AUTOSAR XML (schema 4-0-3)
standard types defined: boolean, float32, float64, sint16, sint32, sint8, uint16, uint32, uint8
package /HelloAutosar
  composition sw component type HA_TopLevel
    component SWC1: type=SWC1
    component SWC2: type=SWC2
    connect SWC1.PPort -> SWC2.RPort
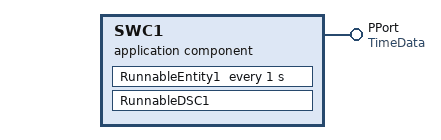
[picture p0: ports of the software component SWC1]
  application sw component type SWC1
    provide port PPort: nonqueued-sender-com-spec{data-element=time, transmission-acknowledge=timeout=1, init-value=Value:0}, provided-interface=TimeData
    behavior IB_SWC1: handle-termination-and-restart=NO-SUPPORT
      timing event TimingEvent: start-on-event=RunnableEntity1, period=1
      data send completed event DataSendCompletedEvent1: start-on-event=RunnableDSC1, event-source=RunnableEntity1/VariableAccess
      runnable RunnableEntity1: can-be-invoked-concurrently=true
        data-send-points:
          access VariableAccess: accessed-variable=PPort.time
      runnable RunnableDSC1: symbol=SWC1_RunnableDSC1
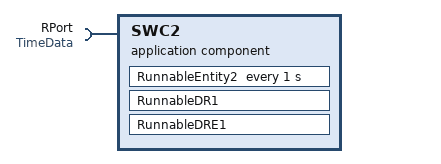
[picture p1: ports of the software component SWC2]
  application sw component type SWC2
    require port RPort: required-interface=TimeData
    behavior IB_SWC2: handle-termination-and-restart=NO-SUPPORT
      timing event TimingEvent: start-on-event=RunnableEntity2, period=1
      data received event DataReceivedEvent1: start-on-event=RunnableDR1, data=RPort.time
      data receive error event DataReceiveErrorEvent1: start-on-event=RunnableDRE1, data=RPort.time
      runnable RunnableEntity2
        data-receive-point-by-arguments:
          access VariableAccess: accessed-variable=RPort.time
      runnable RunnableDR1: can-be-invoked-concurrently=true, symbol=SWC2_RunnableDR1
        data-receive-point-by-arguments:
          access DataReceivePointByArgument: accessed-variable=RPort.time
      runnable RunnableDRE1: can-be-invoked-concurrently=true, symbol=SWC2_RunnableDRE1
        data-receive-point-by-arguments:
          access DataReceivePointByArgument: accessed-variable=RPort.time
package /ImplDataTypes
  impl type IDT_TimeCount: category=VALUE, base-type=uint32, invalid-value=10
package /Interfaces
  sender receiver interface TimeData: invalidation-policy{data-element=time, handle-invalid=KEEP}
    data time: type=IDT_TimeCount
package /System
  ecuc value collection EcucValueCollection: ecu-extract=SystemHA, ecuc-values=[Os, Rte, EcuC]
  system SystemHA: system-version=1.0.0
    root-software-compositions:
      root sw composition prototype RootSwCompositionPrototype: software-composition=HA_TopLevel
